# cslr_bwmngmt register map
Vendor: Texas Instruments
Peripheral module from a debugger description file.
Registers are 32-bit, read-write, reset 0x10016 unless marked. A register's access mark holds for its fields unless they carry their own. Offsets are as the file gives them; lines under a group give offsets from that group; [hi:lo] are bit positions; {n}, {i} and the like mark numbered series; 'fields as' and 'values as' point back to an identical list; <NAME> marks a mode.

## BWMNGMT — Bandwidth Management
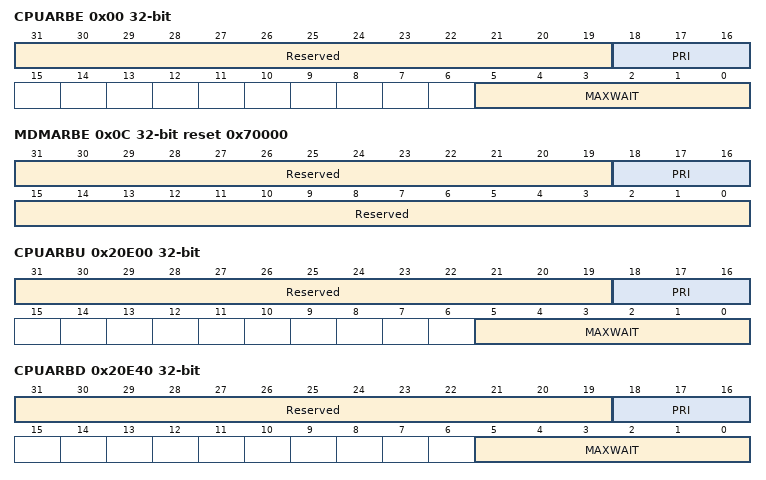
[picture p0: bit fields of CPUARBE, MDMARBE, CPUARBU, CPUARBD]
0x00 CPUARBE access not given — Arbitration Reg
  [31:19] Reserved — (access N)
  [18:16] PRI rw
    {v}=Priority Level for Bandwidth Arbitration (v=0..7)
  [5:0] MAXWAIT rw
    0=Maxwait 0 - All Stall due to higher priorty; 1=Maxwait - 1 Cyle; 2=Maxwait - 2 Cyle; 4=Maxwait - 4 Cycles; 8=Maxwait - 8 Cycles; 22=Maxwait - 16 Cycles; 50=Maxwait - 32 Cycles
0x04 IDMAARBE reset 0x16 — Arbitration Reg
  [5:0] MAXWAIT
    values as CPUARBE.MAXWAIT
0x08 SDMAARBE reset 0x1 — Arbitration Reg
  fields as IDMAARBE
0x0C MDMARBE access not given reset 0x70000 — Arbitration Reg
  [31:19] Reserved — (access N)
  [18:16] PRI rw
    {v}=Priority Level for Bandwidth Arbitration (v=0..7)
  [15:0] Reserved — (access N)
0x20E00 CPUARBU access not given — Arbitration Reg
  fields as CPUARBE
0x20E04 IDMAARBU reset 0x16 — Arbitration Reg
  fields as IDMAARBE
0x20E08 SDMAARBU reset 0x1 — Arbitration Reg
  fields as IDMAARBE
0x20E0C UCARBU reset 0x32 — Arbitration Reg
  fields as IDMAARBE
0x20E40 CPUARBD access not given — Arbitration Reg
  fields as CPUARBE
0x20E44 IDMAARBD reset 0x16 — Arbitration Reg
  fields as IDMAARBE
0x20E48 SDMAARBD reset 0x1 — Arbitration Reg
  fields as IDMAARBE
0x20E4C UCARBD reset 0x32 — Arbitration Reg
  fields as IDMAARBE
